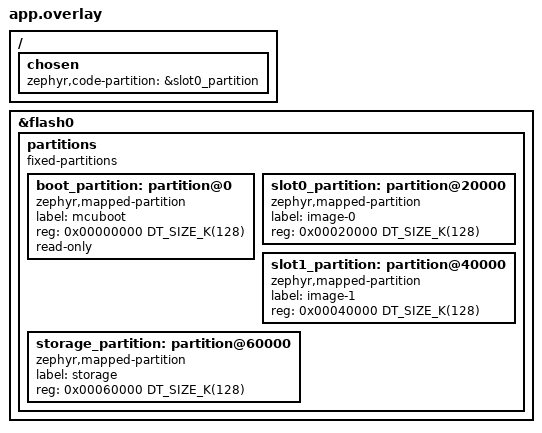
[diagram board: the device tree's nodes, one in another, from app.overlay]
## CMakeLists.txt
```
cmake_minimum_required(VERSION 3.20.0)

find_package(Zephyr REQUIRED HINTS $ENV{ZEPHYR_BASE})
project(test_minimal)

target_sources(app PRIVATE
    src/main.c
)
```

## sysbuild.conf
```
SB_CONFIG_BOOTLOADER_MCUBOOT=y
SB_CONFIG_BOOT_SIGNATURE_TYPE_ECDSA_P256=y
SB_CONFIG_BOOT_SIGNATURE_KEY_FILE="boot_keys/imgtool_key.pem"
SB_CONFIG_MCUBOOT_MODE_OVERWRITE_ONLY=y
```

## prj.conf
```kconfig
# Minimal test app — MCUboot boot chain verification
CONFIG_CONSOLE=y
CONFIG_SERIAL=y
CONFIG_PRINTK=y
CONFIG_BOOTLOADER_MCUBOOT=y
CONFIG_FLASH=y
CONFIG_FLASH_MAP=y
CONFIG_STREAM_FLASH=y
CONFIG_IMG_MANAGER=y
CONFIG_REBOOT=y
CONFIG_STM32H7_BOOT_M4_AT_INIT=n
CONFIG_INIT_ARCH_HW_AT_BOOT=y
CONFIG_HEAP_MEM_POOL_SIZE=4096
# Keep caches disabled — soc_early_init_hook() enables them but
# without MPU configured yet, Cortex-M7 D-Cache causes boot crash
CONFIG_ICACHE=n
CONFIG_DCACHE=n
CONFIG_MAIN_STACK_SIZE=8192
CONFIG_MCUBOOT_IMGTOOL_SIGN_VERSION="0.0.0"
```

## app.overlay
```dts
/ {
    chosen {
        zephyr,code-partition = &slot0_partition;
    };
};

/* MCUboot flash partitions — slots moved to lower 512KB for flash programming compatibility */
&flash0 {
    partitions {
        compatible = "fixed-partitions";
        #address-cells = <1>;
        #size-cells = <1>;
        ranges;

        boot_partition: partition@0 {
            compatible = "zephyr,mapped-partition";
            label = "mcuboot";
            reg = <0x00000000 DT_SIZE_K(128)>;
            read-only;
        };

        slot0_partition: partition@20000 {
            compatible = "zephyr,mapped-partition";
            label = "image-0";
            reg = <0x00020000 DT_SIZE_K(128)>;
        };

        slot1_partition: partition@40000 {
            compatible = "zephyr,mapped-partition";
            label = "image-1";
            reg = <0x00040000 DT_SIZE_K(128)>;
        };

        storage_partition: partition@60000 {
            compatible = "zephyr,mapped-partition";
            label = "storage";
            reg = <0x00060000 DT_SIZE_K(128)>;
        };
    };
};
```

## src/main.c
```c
#include <zephyr/kernel.h>
#include <zephyr/sys/printk.h>
#include <zephyr/dfu/mcuboot.h>

int main(void)
{
	printk("\n===== TestApp Version 0 =====\n");
	boot_write_img_confirmed();
	printk("Image confirmed, running...\n");

	uint32_t count = 0;
	while (1) {
		count++;
		printk("V0 Alive: %u\n", count);
		for (volatile uint32_t i = 0; i < 4000000; i++) {
			__asm__ volatile("nop");
		}
	}
	return 0;
}
```
